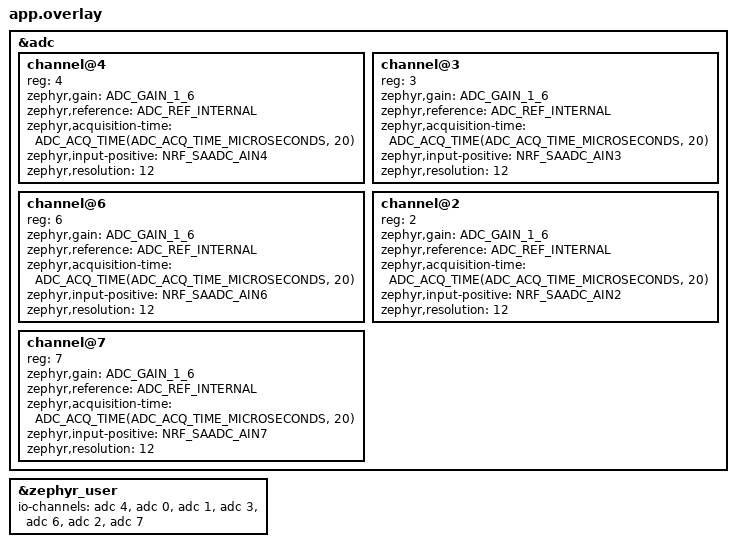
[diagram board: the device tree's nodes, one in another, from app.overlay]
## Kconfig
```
# lyra4-sp1 application Kconfig.

menu "LYRA-4"

# ---- the USB device's identity (M5a, src/sp1_usbd.c) ----
# Through M4e the console came up through Zephyr's sample helper, which hard-codes Zephyr's
# shared test vendor ID. These are ours. ⚠️ Change the PID whenever the set of USB functions
# changes (M5a added MIDI): hosts cache descriptors by VID/PID.
config SP1_USB_VID
	hex "USB vendor ID"
	default 0x2fe3
	help
	  0x2fe3 is Zephyr's test vendor ID, kept only until pid.codes (VID 0x1209,
	  free product IDs for open-source projects) grants LYRA-4 a PID of its own.

config SP1_USB_PID
	hex "USB product ID"
	default 0x5213
	help
	  0x5211 through M4e (console only); 0x5212 from M5a (console + MIDI);
	  0x5213 from M5c (console + MIDI + audio out). Interim: pid.codes
	  1209:4440 is requested (pidcodes/pidcodes.github.com#1301).

config SP1_USB_MANUFACTURER
	string "USB manufacturer string"
	default "Dreambored"

config SP1_USB_PRODUCT
	string "USB product string (the name hosts show for the device and its MIDI port)"
	default "LYRA-4"
	help
	  "lyra4-sp1" through v0.6.x; "LYRA-4" from M5c (Adara). DAWs remember MIDI routings by
	  port name, so a change means re-selecting the port once on each host.

config SP1_USB_MAX_POWER
	int "bMaxPower, in units of 2 mA"
	default 50
	range 0 250
	help
	  iOS rejects accessories claiming more than 100 mA over the camera adapter, and
	  the SP-1 runs from its own battery.

config SP1_AUDIO_BLOCK_FRAMES
	int "Audio block, in frames at 48 kHz"
	default 96
	range 48 240
	help
	  How much audio is rendered at a time: 96 = 2 ms (the default since #32; with 1 queued,
	  8 ms of latency), 240 = 5 ms (25 ms with 2 queued; v0.5.0). Must be a multiple of 48 (1 ms): whole
	  Plaits blocks, and whole 1 kHz groups for Marbles' X/Y. Latency is
	  (CONFIG_I2S_NRFX_TX_BLOCK_COUNT + 3) blocks -- see prj.conf.

config SP1_PLAITS_BLOCK
	int "Plaits block, in samples (12 or 24)"
	default 24
	range 12 24
	depends on SP1_PLAITS
	help
	  How many samples Plaits renders per call (upstream: 12). 24 (#32) halves Plaits'
	  per-call work and our per-Plaits-block glue; modulation, TRIG and MIDI placement move
	  to a 0.5 ms grid and Marbles runs at 2 kHz instead of 4. Every time constant of ours
	  that counted blocks (the TRIG pulse, Plaits' trigger delay, Additive's spectrum
	  update, Chords' crossfade, MIDI's clock and smoothing, Marbles' rate) is expressed in
	  time, so it is the same at either size. Only 12 and 24 are valid.

config SP1_TRIGGER_DELAY_SAMPLES
	int "Plaits' TRIG delay, in samples (whole Plaits blocks)"
	default 24
	range 0 96
	depends on SP1_PLAITS
	help
	  Upstream Plaits delays its TRIG input by 1 ms (48 samples) so a eurorack pitch CV
	  that lags its gate is still caught. In LYRA-4 every TRIG arrives with its pitch, but
	  Plaits averages its V/Oct input over two blocks, so with no delay a Marbles X -> V/Oct
	  strike catches the pitch half-way (host: Modal's attack -1 dB from the settled one,
	  against -18 dB at 0.5 ms; MIDI notes and the quantizer latch are unaffected even at 0).
	  24 = 0.5 ms keeps every attack as it was (#32). Must be whole Plaits blocks.

config SP1_PROFILE_ICACHE
	bool "Diagnostics: flash-cache misses per audio section"
	default n
	depends on SP1_PLAITS
	help
	  Adds a BLK log line with the flash cache's misses per millisecond of audio, by
	  section (#32): whether 2 ms blocks cost more because of per-call work or because the
	  instruction cache refills each time the code switches between Marbles, MIDI and the
	  engine. Reads the NVMC counter a few times per Plaits block (~0.05 % CPU). Off in
	  release builds.

config SP1_LOGBUF_KB
	int "Stored log, in KB of RAM"
	default 96
	range 4 160
	help
	  Everything printk writes is also kept in RAM, newest last, and played back when a
	  terminal next opens the console -- so a session with the USB port in another host's
	  hands (the OP-XY) is not lost (src/sp1_logbuf.h). 96 KB is ~14 minutes of a session.

config SP1_USB_THREADS_BELOW_AUDIO
	bool "Run Zephyr's USB threads below the audio thread (#32)"
	default y
	depends on UDC_NRF_OUT_FAST
	help
	  Moves the udc_nrfx and usbd threads from K_PRIO_COOP(8), above audio, to main's
	  priority, so enumeration, the console and control requests cannot push an audio
	  block over (src/sp1_usbd.c). Only with the MIDI fast path: MIDI must not wait on
	  these threads, or its timestamps would be up to a block late.

config SP1_MIDI
	bool "USB-MIDI in: notes into Plaits, CCs onto both modules (M5a)"
	default y
	depends on SP1_PLAITS
	help
	  A USB-MIDI 1.0 port (feldd's class, third_party/feldd) next to the console.
	  Notes play Plaits, CCs offset parameters on both modules, all configured by
	  config/midi.ini at build time. Costs nothing until a host sends something.
	  n: no MIDI function on the USB device at all.

config SP1_USB_AUDIO
	bool "USB audio out: the SP-1's output to the host, USB Audio Class 1.0 (M5c)"
	default y
	depends on SP1_PLAITS && UDC_NRF_ISO_IN_FAST
	help
	  The output the codecs get, after VOL, sent to the host as a 48 kHz 16-bit
	  stereo input (src/sp1_uac.c). Output only: nothing is received from the host.
	  Packets go out from the USB interrupt through the ISO IN fast path
	  (zephyr-patches/udc_nrf-fast-paths.patch), which is required. Costs nothing
	  until a host opens the stream.

config SP1_PLAITS
	bool "Plaits voice as the audio source (M3)"
	default y
	select CPP
	help
	  y: PLAY triggers the Plaits voice (2-op FM), faders are FREQUENCY /
	  TIMBRE / MORPH / HARMONICS, VOL+/- set the output level.
	  n: the M2 440 Hz test tone instead, with its PLAY / VOL controls, and
	  none of the Plaits code is compiled or linked.

	  This is the FALLBACK SWITCH. If the voice faults or overruns on hardware,
	  set CONFIG_SP1_PLAITS=n in prj.conf and rebuild: everything else in the
	  build (headphone mute, LEDs, power) stays exactly as it was.

config SP1_LYRA
	bool "LYRA-4 four-voice synth as the audio source (experimental)"
	default n
	depends on !SP1_PLAITS
	select CPP
	help
	  y: the LYRA-4 engine (third_party/lyra4) replaces the Plaits voice. Build with
	  lyra.conf (CONFIG_SP1_PLAITS=n, MIDI and USB audio off). Pages, arming and LEDs:
	  src/lyra_ctl.c. Power, charge LEDs, headphone and bootloader code is LYRA-4'.

config SP1_STRING_VOICES
	int "String engine: number of strings (Plaits kNumStrings)"
	range 1 3
	default 2
	depends on SP1_PLAITS
	help
	  How many strings Plaits' String engine rings at once. Upstream is 3.
	  Each TRIG plucks the next string round-robin, so this is how many
	  notes can overlap before the oldest one is re-plucked.

	  2 (default, M3e): every string costs the same, so 2 saves a third of
	  the engine -- 598.6 -> 427.3 instructions/sample in tools/plaits-bench,
	  about 90 % -> 65 % of the audio budget on the SP-1. At 3, String
	  measured 90 % average and 98.5 % peak: it played, with no headroom.

	  Applied at build time to a generated copy of string_engine.h; the
	  vendored file is not modified (see "Plaits overrides" in
	  firmware/CMakeLists.txt). Set it to 3 in prj.conf to A/B the original.

config SP1_PARTICLES
	int "Particle engine: number of particles (Plaits kNumParticles)"
	range 1 6
	default 2
	depends on SP1_PLAITS
	help
	  How many resonant "particles" Plaits' Particle engine runs. Upstream
	  is 6. Plaits divides the density by this count, so the rate of events
	  is the same; fewer means fewer pings ringing at different pitches at
	  once.

	  2 (default, M3h): at 3 (M3f) the SP-1 peaked at 83-100 %, all of it
	  below MORPH centre where the diffuser runs (Adara). Each particle is
	  ~43 instructions/sample. At 6 (upstream) it measured 86 % average /
	  97 % peak. The diffuser is skipped above MORPH centre in any case.

config SP1_MODAL_MODES
	int "Modal engine: number of resonator modes (Plaits kMaxNumModes)"
	range 4 24
	default 12
	depends on SP1_PLAITS
	help
	  Partials of Plaits' modal resonator. Upstream is 24. Must be a
	  multiple of 4 (the resonator renders modes in batches of 4; the build
	  checks). Fewer modes drop the highest partials: the body of a bell
	  stays, its shimmer goes.

	  12 (default, M3g): 8 measured 49 % average / 54 % peak on the SP-1
	  and sounded band-limited (Adara); each batch of 4 modes costs ~100
	  instructions/sample, ~16 %, so 12 is expected near 65 % / 70 %.
	  8 is the fallback. 16 would be ~80 % average -- over the target.

endmenu

source "Kconfig.zephyr"
```

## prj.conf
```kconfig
# lyra4-sp1 M0 — the safety floor.
#
# Deliberately minimal. No USB, no console, no audio, no ADC. Every option
# here either keeps the device recoverable or is required to boot at all.
# Things are ADDED in later milestones, never removed to fix a build.

# ---- Recoverability ----
# The watchdog is the final backstop for a hang on a device with no reset pin.
CONFIG_WATCHDOG=y
# k_sys_fatal_error_handler() in main.c turns any fault into a cold reboot.
CONFIG_REBOOT=y

# ---- Fault containment ----
# HW_STACK_PROTECTION reprograms the MPU stack guard on every context switch.
# sp1-tape-looper measured that at ~1 % at the corner and turned it off in
# favour of the cheaper STACK_SENTINEL canary (which Kconfig excludes while
# MPU_STACK_GUARD is on). M0 has CPU to spare and no audio deadline yet, so
# keep the stronger guard here and revisit at M2 when the deadline is real.
CONFIG_HW_STACK_PROTECTION=y

# ---- USB CDC ACM console (M1c) ----
# Exists to make two things possible that are miserable blind: calibrating the
# battery divider, and building the button-ladder threshold tables in M1d.
#
# device_next rather than the legacy CONFIG_USB_DEVICE_STACK: legacy is smaller but
# deprecated, mass storage later would need device_next anyway, and this is the path
# sp1-tape-looper proved on this board and this Zephyr version.
CONFIG_CONSOLE=y
CONFIG_PRINTK=y
CONFIG_SERIAL=y
CONFIG_UART_CONSOLE=y
CONFIG_UART_LINE_CTRL=y
CONFIG_UART_INTERRUPT_DRIVEN=y

CONFIG_USB_DEVICE_STACK_NEXT=y
CONFIG_USBD_CDC_ACM_CLASS=y
# The app owns the single USBD context; do not let the CDC SYS_INIT build a second
# private one that would fight for the controller.
CONFIG_CDC_ACM_SERIAL_INITIALIZE_AT_BOOT=n
CONFIG_HWINFO=y
# The device's identity (VID/PID, names, bMaxPower) is CONFIG_SP1_USB_* in firmware/Kconfig
# since M5a, set by src/sp1_usbd.c rather than Zephyr's sample helper.

# ---- USB-MIDI (M5a) ----
# feldd's MIDI 1.0 class (third_party/feldd) queues its transmit side in a ring buffer.
CONFIG_RING_BUFFER=y
# #32: MIDI is received in the USB interrupt (zephyr-patches/udc_nrf-fast-paths.patch):
# ~110 us of thread hand-offs per message down to a few us, and stamped in the interrupt.
# That frees Zephyr's USB threads to run below audio (CONFIG_SP1_USB_THREADS_BELOW_AUDIO,
# on by default with it).
CONFIG_UDC_NRF_OUT_FAST=y
# M5c: USB audio out sends every packet from the USB interrupt (Ryan Gilmore's ISO IN fast
# path, same patch). CONFIG_SP1_USB_AUDIO (default y) needs it.
CONFIG_UDC_NRF_ISO_IN_FAST=y

CONFIG_LOG=n
CONFIG_ASSERT=n

# The USB stack's init and printf need more main stack than the bare power build.
# 3 KB from M3 (was 2 KB): main now uses the FPU (fader smoothing), so every exception
# taken on its stack carries the extended FP frame, and it calls printk with more args.
CONFIG_MAIN_STACK_SIZE=3072

# ---- Clocking ----
# Matches what the bootloader leaves behind. Do not change without reading
# docs/SAFETY.md -- re-initialising bootloader-owned clocks is on the "do not"
# list for this board.
CONFIG_CLOCK_CONTROL=y
CONFIG_CLOCK_CONTROL_NRF_K32SRC_SYNTH=y


# ---- LED rows on hardware PWM (M1a) ----
# Hardware PWM costs no CPU (EasyDMA), unlike the software PWM sp1-tape-looper
# uses -- which needed a zero-latency IRQ to stop flicker and would compete with
# the audio deadline from M2 on. Do not replace this with a software PWM.
CONFIG_PWM=y
CONFIG_PWM_NRFX=y

# ---- Battery voltage (M1b) ----
# SAADC on AIN4. Only the battery channel for now; the faders join in M1c.
CONFIG_ADC=y

# ---- Output naming ----
# Renames build/zephyr/zephyr.{elf,bin,hex,map,...} to lyra4-sp1.{elf,bin,hex,map,...}.
# The build/zephyr/ subdirectory itself is unaffected -- that name comes from the
# Zephyr CMake target, not this option.
CONFIG_KERNEL_BIN_NAME="lyra4-sp1"

# ---- Audio output (M2) ----
# I2C to the two codecs (CS42L42 headphone at 0x48, TAS2505 speaker amp at 0x18),
# and the I2S stream as a CLOCK SLAVE on both clocks -- see sp1_audio.h for the
# topology. Same three options sp1-tape-looper proved on this board.
CONFIG_I2C=y
CONFIG_I2S=y
CONFIG_I2S_NRFX=y
# ---- latency (M5b, Adara: "over 30 ms is a no-go"; #32: 10 ms) ----
# Sound leaves LYRA-4 (queued blocks + 3) x the block length after what caused it: one block
# to place a MIDI message on time, the queued blocks, the DMA's next one and the one
# playing (sp1_audio.c). 5 ms x 4 queued was 35 ms, 5 ms x 2 was 25 ms (v0.5.0), 2 ms x 2 was
# 10 ms, and 2 ms x 1 is 8 ms (#32), affordable since Plaits renders 24-sample blocks. The block
# length is CONFIG_SP1_AUDIO_BLOCK_FRAMES (firmware/Kconfig). What it costs: a block that runs
# long has (queued + 1) x 2 = 4 ms -- 200 % of its budget -- before the output runs dry. The
# heaviest session measured (Chords, Marbles, OUTxAUX, drive, a CC stream; 2026-10-04) peaked at
# 96.8 %, and USB enumeration no longer runs above audio.
CONFIG_I2S_NRFX_TX_BLOCK_COUNT=1

# ---- CPU per thread, for the log (M5b diagnostics; src/sp1_threads.h) ----
# The audio sections cannot see what preempts them -- the USB stack runs above audio -- so
# every thread's share is counted at each context switch, on the DWT cycle counter (the
# kernel's own tick would be 30 us coarse). A few cycles per switch.
CONFIG_THREAD_RUNTIME_STATS=y
CONFIG_THREAD_RUNTIME_STATS_USE_TIMING_FUNCTIONS=y
CONFIG_TIMING_FUNCTIONS=y
CONFIG_THREAD_MONITOR=y
CONFIG_THREAD_NAME=y

# Floating-point unit. Nothing in M2 uses float -- the tone and the meter are
# integer-only on purpose -- but Plaits is float throughout from M3. Turning the FPU
# on HERE means M3 changes one thing (the synth), not two (the synth and the
# FP context-switch behaviour).
CONFIG_FPU=y
# Preserve FP registers across context switches. CONFIG_FPU alone is Zephyr's
# UNSHARED mode: FP state is not saved when threads switch. Plaits (float) will run in
# the audio thread, and any float in main, USB or an ISR would silently corrupt it --
# and with the hard-float ABI the compiler may use VFP registers for plain data moves
# too. Set now, with the FPU, so M3 does not inherit a latent corruption bug.
CONFIG_FPU_SHARING=y

# ---- M3: the Plaits voice ----
# The fallback switch: n = the M2 test tone, and no Plaits code is built at all.
CONFIG_SP1_PLAITS=y
# Plaits is C++ (no exceptions, no RTTI -- the Zephyr defaults) and needs <algorithm>
# and <cmath>, which the minimal C++ library does not provide.
CONFIG_CPP=y
CONFIG_STD_CPP14=y
CONFIG_GLIBCXX_LIBCPP=y
# ⚠️ The audio thread runs at K_PRIO_PREEMPT(0) and MUST outrank main, so main moves
# to 1. From M3 the audio work is ~half the CPU; at equal priority the ADC scan and
# every printk would compete with the audio deadline. See sp1_audio.h.
CONFIG_MAIN_THREAD_PRIORITY=1
```

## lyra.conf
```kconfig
# LYRA-4 build overlay:  west build ... -- -DOVERLAY... use: -DEXTRA_CONF_FILE=lyra.conf
CONFIG_SP1_PLAITS=n
CONFIG_SP1_LYRA=y
CONFIG_SP1_MIDI=n
CONFIG_SP1_USB_AUDIO=n
CONFIG_SP1_USB_PRODUCT="LYRA-4"
CONFIG_SP1_USB_MANUFACTURER="Dreambored"
```

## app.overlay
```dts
/*
 * lyra4-sp1 application overlay.
 *
 * M1d adds the four faders, APPENDED after the battery so it keeps io-channel
 * index 0 and sp1_batt.c never has to be renumbered.
 *
 * `reg` is chosen to equal the AIN number for the faders, which makes the mapping
 * readable against the schematic. The io-channel INDEX is what C uses, and the two
 * are deliberately different things -- see sp1_controls.c.
 *
 * Gain 1/6 + ADC_REF_INTERNAL matches the ladder channels in the board DTS, and
 * that pairing is load-bearing: published millivolt threshold tables are only
 * valid under the ADC configuration they were measured in. sp1-midi uses gain 1/4
 * with VDD/4 -- never mix the two.
 */

#include <zephyr/dt-bindings/adc/adc.h>
#include <zephyr/dt-bindings/adc/nrf-saadc.h>

&adc {
	/* Battery voltage, P0.28 / AIN4, via an on-board divider of UNKNOWN ratio.
	 * See sp1_batt.h for how to calibrate it without opening the device. */
	channel@4 {
		reg = <4>;
		zephyr,gain = "ADC_GAIN_1_6";
		zephyr,reference = "ADC_REF_INTERNAL";
		zephyr,acquisition-time = <ADC_ACQ_TIME(ADC_ACQ_TIME_MICROSECONDS, 20)>;
		zephyr,input-positive = <NRF_SAADC_AIN4>;
		zephyr,resolution = <12>;
	};
};

&adc {
	/* Fader 1, P0.05 / AIN3 */
	channel@3 {
		reg = <3>;
		zephyr,gain = "ADC_GAIN_1_6";
		zephyr,reference = "ADC_REF_INTERNAL";
		zephyr,acquisition-time = <ADC_ACQ_TIME(ADC_ACQ_TIME_MICROSECONDS, 20)>;
		zephyr,input-positive = <NRF_SAADC_AIN3>;
		zephyr,resolution = <12>;
	};
	/* Fader 2, P0.30 / AIN6 */
	channel@6 {
		reg = <6>;
		zephyr,gain = "ADC_GAIN_1_6";
		zephyr,reference = "ADC_REF_INTERNAL";
		zephyr,acquisition-time = <ADC_ACQ_TIME(ADC_ACQ_TIME_MICROSECONDS, 20)>;
		zephyr,input-positive = <NRF_SAADC_AIN6>;
		zephyr,resolution = <12>;
	};
	/* Fader 3, P0.04 / AIN2 */
	channel@2 {
		reg = <2>;
		zephyr,gain = "ADC_GAIN_1_6";
		zephyr,reference = "ADC_REF_INTERNAL";
		zephyr,acquisition-time = <ADC_ACQ_TIME(ADC_ACQ_TIME_MICROSECONDS, 20)>;
		zephyr,input-positive = <NRF_SAADC_AIN2>;
		zephyr,resolution = <12>;
	};
	/* Fader 4, P0.31 / AIN7 */
	channel@7 {
		reg = <7>;
		zephyr,gain = "ADC_GAIN_1_6";
		zephyr,reference = "ADC_REF_INTERNAL";
		zephyr,acquisition-time = <ADC_ACQ_TIME(ADC_ACQ_TIME_MICROSECONDS, 20)>;
		zephyr,input-positive = <NRF_SAADC_AIN7>;
		zephyr,resolution = <12>;
	};
};

&zephyr_user {
	/* ORDER IS THE C-VISIBLE INDEX. Battery must stay index 0.
	 *   0 battery   1 ladder-tracks   2 ladder-vol
	 *   3 fader1    4 fader2          5 fader3       6 fader4
	 * See the IO_* defines in sp1_controls.c -- they must match this order. */
	io-channels = <&adc 4>,
		      <&adc 0>, <&adc 1>,
		      <&adc 3>, <&adc 6>, <&adc 2>, <&adc 7>;
};
```

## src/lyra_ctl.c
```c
#include "lyra_ctl.h"
#include <string.h>

static float params[LYRA_P_COUNT];
static float pub_prev[LYRA_P_COUNT];
static bool  quantize, quantize_prev;
static uint32_t phase_ms;
/* Unarmed-fader touch detection, for the LEDs only: a T blinks only while its fader is being
 * moved without being armed. Reference position + a hold timer; never feeds the parameters. */
#define TOUCH_DELTA   0.010f    /* 1 % of travel from the reference counts as movement */
#define TOUCH_HOLD_MS 1200u     /* keep blinking this long after the last movement     */
static float    touch_ref[4];
static uint32_t touch_ms[4];
static int      touch_bank = -1;

/* Voice trigger mode. LATCH: T toggles. MOMENTARY: sounds while held ("••" + FFWD). */
static int      mode;
static uint8_t  mom[4];            /* bit0: T held, bit1: PLAY held */

/* Defaults: the LIRA-4 patch's, except the delay feedback (see LYRA4_CONTROL_MAP.md 3c). */
#define DEF_DFB 0.30f
static const float kDefaults[LYRA_UI_BANKS][LYRA_UI_FADERS] = {
	{ 0.4f, 0.6f, 0.5f, 0.5f },      /* page 0: tune 1-4                    */
	{ 0.0f, 0.0f, 0.5f, 0.5f },      /* page 1: mod12, mod34, sharp12, 34   */
	{ 0.5f, DEF_DFB, 0.5f, 0.1f },   /* page 2: time, feedback, mix, mod    */
	{ 0.6f, 0.7f, 0.5f, 0.5f },      /* page 3: lfo A, lfo B, drive, dmix   */
	{ 0.5f, 0.0f, 0.5f, 0.5f },      /* page 0 + "••": pitch, hold, -, -    */
};

static void set_defaults(void)
{
	memset(params, 0, sizeof(params));
	params[LYRA_P_SOURCE12] = 2.0f;        /* the other pair */
	params[LYRA_P_SOURCE34] = 2.0f;
	params[LYRA_P_VOLUME] = 1.0f;          /* output level is LYRA-4' VOL+/VOL- */
	params[LYRA_P_DSOURCE] = 2.0f;
}

void lyra_ctl_init(void)
{
	set_defaults();
	lyra_ui_init(kDefaults);
	quantize = quantize_prev = false;
	phase_ms = 0;
	touch_bank = -1;
	for (int i = 0; i < 4; i++) touch_ms[i] = 0u;
	mode = LYRA_MODE_LATCH;
	for (int i = 0; i < 4; i++) mom[i] = 0u;
	memcpy(pub_prev, params, sizeof(params));
}

void lyra_ctl_enter(const uint16_t raw[4])
{
	/* Voices are off on every entry to ON; toggles keep their state. */
	for (int i = 0; i < 4; i++) { params[LYRA_P_SENSOR1 + i] = 0.0f; mom[i] = 0u; }
	lyra_ui_enter(raw);
	touch_bank = -1;
}

int lyra_ctl_mode(void) { return mode; }

static void voice_on(int i) { params[LYRA_P_SENSOR1 + i] = 1.0f; }
static void voice_off(int i) { params[LYRA_P_SENSOR1 + i] = 0.0f; }

/* Changing mode silences everything so no voice is left latched or held by the old mode. */
static void set_mode(int m)
{
	mode = m;
	for (int i = 0; i < 4; i++) { voice_off(i); mom[i] = 0u; }
}

static float flip(float v) { return v > 0.5f ? 0.0f : 1.0f; }
static float cycle_src(float v) { int s = (int)(v + 0.5f); return (float)(s == 2 ? 0 : (s == 0 ? 1 : 2)); }

static void fill_from_banks(void)
{
	for (int i = 0; i < 4; i++) {
		params[LYRA_P_TUNE1 + i] = lyra_ui_value(0, i);
	}
	params[LYRA_P_MOD12]   = lyra_ui_value(1, 0);
	params[LYRA_P_MOD34]   = lyra_ui_value(1, 1);
	params[LYRA_P_SHARP12] = lyra_ui_value(1, 2);
	params[LYRA_P_SHARP34] = lyra_ui_value(1, 3);
	params[LYRA_P_DTIME]   = lyra_ui_value(2, 0);
	params[LYRA_P_DFB]     = lyra_ui_value(2, 1);
	params[LYRA_P_DMIXD]   = lyra_ui_value(2, 2);
	params[LYRA_P_DMOD]    = lyra_ui_value(2, 3);
	params[LYRA_P_LFOA]    = lyra_ui_value(3, 0);
	params[LYRA_P_LFOB]    = lyra_ui_value(3, 1);
	params[LYRA_P_DRIVE]   = lyra_ui_value(3, 2);
	params[LYRA_P_DMIX]    = lyra_ui_value(3, 3);
	params[LYRA_P_PITCH]   = lyra_ui_value(LYRA_UI_SHIFT, 0);
	params[LYRA_P_HOLD]    = lyra_ui_value(LYRA_UI_SHIFT, 1);
}

static void buttons(bool fn, uint32_t pressed, uint32_t released)
{
	const int pg = lyra_ui_page();
	const uint32_t tm[4] = { LYRA_B_T1, LYRA_B_T2, LYRA_B_T3, LYRA_B_T4 };

	/* Momentary releases count wherever you are: a held voice must always be able to close. */
	for (int i = 0; i < 4; i++) {
		if ((released & tm[i]) && (mom[i] & 1u)) mom[i] &= (uint8_t)~1u;
		if ((released & LYRA_B_PLAY) && (mom[i] & 2u)) mom[i] &= (uint8_t)~2u;
		if (mode == LYRA_MODE_MOMENTARY && mom[i] == 0u && params[LYRA_P_SENSOR1 + i] > 0.5f
		    && ((released & tm[i]) || (released & LYRA_B_PLAY))) voice_off(i);
	}

	if (fn && pg == 0 && (pressed & LYRA_B_FFWD)) {
		set_mode(mode == LYRA_MODE_MOMENTARY ? LYRA_MODE_LATCH : LYRA_MODE_MOMENTARY);
	}

	if (!fn) {
		if (pressed & LYRA_B_RWD)  lyra_ui_set_page((pg + LYRA_UI_PAGES - 1) % LYRA_UI_PAGES);
		if (pressed & LYRA_B_FFWD) lyra_ui_set_page((pg + 1) % LYRA_UI_PAGES);
	}
	if ((pressed & LYRA_B_PLAY) && !fn) {
		if (mode == LYRA_MODE_MOMENTARY) {
			for (int i = 0; i < 4; i++) { mom[i] |= 2u; voice_on(i); }
		} else {
			bool all_on = true;
			for (int i = 0; i < 4; i++) if (params[LYRA_P_SENSOR1 + i] < 0.5f) all_on = false;
			for (int i = 0; i < 4; i++) params[LYRA_P_SENSOR1 + i] = all_on ? 0.0f : 1.0f;
		}
	}
	const uint32_t t[4] = { LYRA_B_T1, LYRA_B_T2, LYRA_B_T3, LYRA_B_T4 };
	for (int i = 0; i < 4; i++) {
		if (!(pressed & t[i])) continue;
		if (fn) {
			if (pg != 0) continue;
			switch (i) {
			case 0: params[LYRA_P_FAST12] = flip(params[LYRA_P_FAST12]); break;
			case 1: params[LYRA_P_FAST34] = flip(params[LYRA_P_FAST34]); break;
			case 2: params[LYRA_P_VIBRATO] = flip(params[LYRA_P_VIBRATO]); break;
			default: quantize = !quantize; break;
			}
			continue;
		}
		switch (pg) {
		case 0:
				if (mode == LYRA_MODE_MOMENTARY) { mom[i] |= 1u; voice_on(i); }
				else { params[LYRA_P_SENSOR1 + i] = flip(params[LYRA_P_SENSOR1 + i]); }
				break;
		case 1:
			if (i == 0) params[LYRA_P_SOURCE12] = cycle_src(params[LYRA_P_SOURCE12]);
			if (i == 1) params[LYRA_P_SOURCE34] = cycle_src(params[LYRA_P_SOURCE34]);
			if (i == 2) params[LYRA_P_TOTALFB] = flip(params[LYRA_P_TOTALFB]);
			break;
		case 2:
			if (i == 0) params[LYRA_P_DWAVE] = flip(params[LYRA_P_DWAVE]);
			if (i == 1) params[LYRA_P_DSOURCE] = cycle_src(params[LYRA_P_DSOURCE]);
			break;
		default:
			if (i == 0) params[LYRA_P_LFOLINK] = flip(params[LYRA_P_LFOLINK]);
			if (i == 1) params[LYRA_P_LFOANDOR] = flip(params[LYRA_P_LFOANDOR]);
			break;
		}
	}
}

bool lyra_ctl_tick(uint32_t dt_ms, const uint16_t raw[4], bool scan_valid, bool ladder_active,
		   bool fn_held, uint32_t pressed, uint32_t released)
{
	phase_ms = (phase_ms + dt_ms) % 800u;
	(void)lyra_ui_tick(raw, scan_valid, ladder_active, fn_held);
	/* LED-only touch tracking. */
	if (lyra_ui_bank() != touch_bank) {
		touch_bank = lyra_ui_bank();
		for (int i = 0; i < 4; i++) { touch_ref[i] = lyra_ui_pos(i); touch_ms[i] = 0u; }
	}
	for (int i = 0; i < 4; i++) {
		const float d = lyra_ui_pos(i) - touch_ref[i];
		if (lyra_ui_armed(i)) {
			touch_ref[i] = lyra_ui_pos(i);
			touch_ms[i] = 0u;
		} else if (d > TOUCH_DELTA || d < -TOUCH_DELTA) {
			touch_ref[i] = lyra_ui_pos(i);
			touch_ms[i] = TOUCH_HOLD_MS;
		} else if (touch_ms[i] > 0u) {
			touch_ms[i] = touch_ms[i] > dt_ms ? touch_ms[i] - dt_ms : 0u;
		}
	}
	fill_from_banks();
	/* A ladder press is exactly when a button edge arrives; the edge itself is real. */
	buttons(fn_held, pressed, released);
	const bool changed = memcmp(pub_prev, params, sizeof(params)) != 0 || quantize != quantize_prev;
	memcpy(pub_prev, params, sizeof(params));
	quantize_prev = quantize;
	return changed;
}

const float *lyra_ctl_params(void) { return params; }
bool lyra_ctl_quantize(void) { return quantize; }

/* Three-way source selector (2 = default source, 0 = alternative source, 1 = off):
 * bright = default source, dim = alternative source, dark = off. */
static uint8_t tri_level(float v)
{
	const int s = (int)(v + 0.5f);
	return s == 2 ? LYRA_TRK_ON : (s == 0 ? LYRA_TRK_MID : 0u);
}

static uint8_t bin_level(float v) { return v > 0.5f ? LYRA_TRK_ON : 0u; }

/* Steady level shown by T1-T4 on the current page.
 *   page 1: voice on/off.
 *   page 2: T1, T2 source (other pair bright / LFO-or-feedback dim / off dark); T3 total feedback.
 *   page 3: T1 delay waveform; T2 delay source (LFO bright / own tap dim / off dark).
 *   page 4: T1 LFO link; T2 LFO and/or. */
static uint8_t track_level(int i)
{
	switch (lyra_ui_page()) {
	case 0: return bin_level(params[LYRA_P_SENSOR1 + i]);
	case 1: if (i == 0) return tri_level(params[LYRA_P_SOURCE12]);
		if (i == 1) return tri_level(params[LYRA_P_SOURCE34]);
		if (i == 2) return bin_level(params[LYRA_P_TOTALFB]);
		return 0u;
	case 2: if (i == 0) return bin_level(params[LYRA_P_DWAVE]);
		if (i == 1) return tri_level(params[LYRA_P_DSOURCE]);
		return 0u;
	default: if (i == 0) return bin_level(params[LYRA_P_LFOLINK]);
		if (i == 1) return bin_level(params[LYRA_P_LFOANDOR]);
		return 0u;
	}
}

void lyra_ctl_leds(uint8_t track[4], uint8_t play[4])
{
	const bool phase = phase_ms < 400u;
	if (lyra_ui_bank() == LYRA_UI_SHIFT) {
		/* "••" held on page 1: T1-T4 are the four switches, shown steady. Only the pitch and
		 * hold faders (0, 1) are live here; faders 2 and 3 are unused and never signal. */
		const bool sw[4] = { params[LYRA_P_FAST12] > 0.5f, params[LYRA_P_FAST34] > 0.5f,
				     params[LYRA_P_VIBRATO] > 0.5f, quantize };
		for (int i = 0; i < 4; i++) track[i] = sw[i] ? LYRA_TRK_ON : 0u;
		for (int i = 0; i < 4; i++) play[i] = 0u;
		/* Page LED (top) dims; it blinks only while an unarmed live fader (pitch, hold) is
		 * being moved. The second side LED shows momentary mode. */
		bool waiting = false;
		for (int i = 0; i <= 1; i++) if (!lyra_ui_armed(i) && touch_ms[i] > 0u) waiting = true;
		play[3] = waiting ? (phase ? LYRA_SIDE_DIM : LYRA_SIDE_LOW) : LYRA_SIDE_DIM;
		play[2] = (mode == LYRA_MODE_MOMENTARY) ? LYRA_SIDE_FULL : 0u;
		return;
	}
	for (int i = 0; i < 4; i++) {
		const uint8_t lvl = track_level(i);
		if (lyra_ui_armed(i) || touch_ms[i] == 0u) {
			track[i] = lvl;
		} else if (lvl >= LYRA_TRK_ON) {
			/* Unarmed fader being moved: slow blink. Bright states blink bright/low; dim and
			 * dark states blink their level (at least the dark-state glimmer) and dark. */
			track[i] = phase ? LYRA_TRK_ON : LYRA_TRK_ON_LO;
		} else {
			track[i] = phase ? (lvl > LYRA_TRK_OFF_HI ? lvl : LYRA_TRK_OFF_HI) : 0u;
		}
	}
	for (int i = 0; i < 4; i++) play[i] = 0u;
	/* Page 1 is the TOP side LED. LED index 0 is the "••" end and index 3 is next to PLAY, so
	 * the page order runs from index 3 down to index 0 (user: page 1 = top, page 4 = bottom). */
	play[3 - lyra_ui_page()] = (lyra_ui_bank() == LYRA_UI_SHIFT) ? LYRA_SIDE_DIM : LYRA_SIDE_FULL;
}
```

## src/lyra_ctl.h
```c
/*
 * LYRA-4 control layer: pages, latching voices, toggles, LEDs, parameter vector.
 * Plain C99, no OS. Sits on lyra_ui (fader arming). The LYRA-4 glue (main.c) feeds it
 * button edges and fader reads and publishes `params` to the audio thread.
 *
 * Parameter ids below MIRROR lyra4::Param (lyra4_engine.h); sp1_lyra.cc static_asserts that.
 * Control map: LYRA4_CONTROL_MAP.md. VOL+/VOL- (output level) and the "••" power gestures
 * stay in LYRA-4' main loop and are not handled here.
 */
#ifndef LYRA_CTL_H
#define LYRA_CTL_H

#include "lyra_ui.h"

enum {
	LYRA_P_TUNE1 = 0, LYRA_P_TUNE2, LYRA_P_TUNE3, LYRA_P_TUNE4, LYRA_P_PITCH,
	LYRA_P_MOD12, LYRA_P_MOD34, LYRA_P_SHARP12, LYRA_P_SHARP34,
	LYRA_P_SOURCE12, LYRA_P_SOURCE34, LYRA_P_TOTALFB,
	LYRA_P_HOLD, LYRA_P_VIBRATO, LYRA_P_FAST12, LYRA_P_FAST34,
	LYRA_P_SENSOR1, LYRA_P_SENSOR2, LYRA_P_SENSOR3, LYRA_P_SENSOR4,
	LYRA_P_VOLUME, LYRA_P_DRIVE, LYRA_P_DMIX,
	LYRA_P_DWAVE, LYRA_P_DSOURCE,
	LYRA_P_DMOD, LYRA_P_DFB, LYRA_P_DMIXD, LYRA_P_DTIME,
	LYRA_P_LFOA, LYRA_P_LFOB, LYRA_P_LFOLINK, LYRA_P_LFOANDOR,
	LYRA_P_COUNT
};

/* Button edges (pressed / released this tick; PLAY and T1-T4 matter for `released`). */
#define LYRA_B_PLAY 0x01u
#define LYRA_B_T1   0x02u
#define LYRA_B_T2   0x04u
#define LYRA_B_T3   0x08u
#define LYRA_B_T4   0x10u
#define LYRA_B_RWD  0x20u
#define LYRA_B_FFWD 0x40u

/* Voice trigger modes ("••" + FFWD = momentary; the same press again = latch). */
enum { LYRA_MODE_LATCH = 0, LYRA_MODE_MOMENTARY };
int   lyra_ctl_mode(void);

/* Quantized-tuning switch (page 0, "••" + T4). Not an engine Param: applied via Options. */
void  lyra_ctl_init(void);
void  lyra_ctl_enter(const uint16_t raw[4]);    /* entry to ON: voices off, faders disarmed */
/* One control tick. Returns true if `params` or `quantize` changed. */
bool  lyra_ctl_tick(uint32_t dt_ms, const uint16_t raw[4], bool scan_valid, bool ladder_active,
		    bool fn_held, uint32_t pressed, uint32_t released);
const float *lyra_ctl_params(void);
bool  lyra_ctl_quantize(void);
/* Side (play) row levels, 0..255. The page indicator and the mode LED are deliberately
 * dim: they are always on. The track row keeps full range. */
#define LYRA_SIDE_FULL 100u
#define LYRA_SIDE_DIM   45u     /* shift layer */
#define LYRA_SIDE_LOW   10u     /* low half of the "touching an unpicked fader" blink */
/* Track row (T1-T4) levels. Half the old full-brightness; the shutdown animation is untouched. */
#define LYRA_TRK_ON     130u
#define LYRA_TRK_MID     45u    /* three-way selectors: the alternative source */
#define LYRA_TRK_ON_LO   50u    /* low half of the blink on an "on" T */
#define LYRA_TRK_OFF_HI  40u    /* high half of the blink on an "off" T */
/* LED levels 0..255 for the track row (T1-T4) and the play row (page indicator). */
void  lyra_ctl_leds(uint8_t track[4], uint8_t play[4]);

#endif
```

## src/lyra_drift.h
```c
/* LYRA-4: "has a hand touched a fader since the mark?" that survives common-mode drift.
 *
 * The stock check (sp1_controls_activity) flags any fader that has moved SP1_TOUCH_COUNTS
 * (80) from the value it had when "••" went down, and that flag cancels the 3 s shutdown.
 * A loud, changing output loads the supply rail the faders are read from, so ALL four
 * faders read a little low (or high) together, in proportion to their value. LYRA holds
 * "••" for a long time while the sound is moving, so that drift can cross 80 counts with
 * no hand on anything.
 *
 * A hand moves one or two faders. Drift moves every fader by the same FACTOR. So: estimate
 * the common factor from the faders that are far enough off zero to measure it (median of
 * their now/mark ratios, needs at least 3), bound it, and judge each fader against
 * mark * factor. With fewer than 3 usable faders, or a factor outside the bound, the factor
 * is 1 and this is exactly the stock test.
 *
 * Pure function, no state, no Zephyr: host-tested in lyra_drifttest.c.
 */
#ifndef LYRA_DRIFT_H
#define LYRA_DRIFT_H

#include <stdint.h>

#define LYRA_DRIFT_TOUCH     80      /* same as SP1_TOUCH_COUNTS                          */
#define LYRA_DRIFT_MIN_MARK  1200    /* a fader below this says too little about gain     */
#define LYRA_DRIFT_G_MIN     0.93f   /* more drift than +-7 % is not drift we trust       */
#define LYRA_DRIFT_G_MAX     1.07f

/* Returns the index (0..3) of the first fader judged touched, or -1 if none.
 * `gain_out` (optional) receives the common factor that was used. */
static inline int lyra_fader_touched(const uint16_t now[4], const uint16_t mark[4], float *gain_out)
{
	float r[4];
	int n = 0;
	for (int i = 0; i < 4; i++) {
		if (mark[i] >= LYRA_DRIFT_MIN_MARK) {
			r[n++] = (float)now[i] / (float)mark[i];
		}
	}
	float g = 1.0f;
	if (n >= 3) {
		for (int a = 1; a < n; a++) {            /* insertion sort, n <= 4 */
			const float v = r[a];
			int b = a - 1;
			while (b >= 0 && r[b] > v) { r[b + 1] = r[b]; b--; }
			r[b + 1] = v;
		}
		g = (n == 3) ? r[1] : 0.5f * (r[1] + r[2]);
		if (g < LYRA_DRIFT_G_MIN || g > LYRA_DRIFT_G_MAX) {
			g = 1.0f;
		}
	}
	if (gain_out) {
		*gain_out = g;
	}
	for (int i = 0; i < 4; i++) {
		const float expect = (float)mark[i] * g;
		const float d = (float)now[i] - expect;
		if (d >= (float)LYRA_DRIFT_TOUCH || d <= -(float)LYRA_DRIFT_TOUCH) {
			return i;
		}
	}
	return -1;
}

#endif
```

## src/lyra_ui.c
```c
#include "lyra_ui.h"
#include <math.h>

static float stored[LYRA_UI_BANKS][LYRA_UI_FADERS];
static float pos[LYRA_UI_FADERS];
static float prev[LYRA_UI_FADERS];
static float lock_ref[LYRA_UI_FADERS];
static float lastraw[LYRA_UI_FADERS];
static bool  armed[LYRA_UI_FADERS];
static bool  locked[LYRA_UI_FADERS];
static int   page;
static int   bank;
static bool  seeded;

static float clamp01(float v) { return v < 0.0f ? 0.0f : (v > 1.0f ? 1.0f : v); }
static float to01(uint16_t r) { return clamp01((float)r / LYRA_UI_FULL); }

void lyra_ui_init(const float d[LYRA_UI_BANKS][LYRA_UI_FADERS])
{
	for (int b = 0; b < LYRA_UI_BANKS; b++)
		for (int i = 0; i < LYRA_UI_FADERS; i++)
			stored[b][i] = d ? clamp01(d[b][i]) : 0.5f;
	page = 0; bank = 0; seeded = false;
	for (int i = 0; i < LYRA_UI_FADERS; i++) { pos[i] = prev[i] = lock_ref[i] = 0.0f; armed[i] = false; locked[i] = false; }
}

/* Decide, for the bank now showing, which faders start armed or locked. */
static void disarm_all(void)
{
	for (int i = 0; i < LYRA_UI_FADERS; i++) {
		prev[i] = pos[i];
		lock_ref[i] = pos[i];
		if (fabsf(stored[bank][i] - pos[i]) <= LYRA_UI_WINDOW) {
			/* Already on the value: no jump possible beyond the window. */
			armed[i] = true;
			locked[i] = false;
		} else {
			armed[i] = false;
			locked[i] = true;
		}
	}
}

void lyra_ui_enter(const uint16_t raw[LYRA_UI_FADERS])
{
	for (int i = 0; i < LYRA_UI_FADERS; i++) { pos[i] = lastraw[i] = to01(raw[i]); }
	page = 0; bank = 0; seeded = true;
	disarm_all();
}

void lyra_ui_set_page(int p)
{
	if (p < 0 || p >= LYRA_UI_PAGES || p == page) return;
	page = p; bank = p;
	disarm_all();
}

uint32_t lyra_ui_tick(const uint16_t raw[LYRA_UI_FADERS], bool scan_valid,
		      bool ladder_active, bool shift_held)
{
	if (!seeded) return 0u;

	/* Shift layer exists on page 0 only. Entering or leaving it is a bank change. */
	const int want = (page == 0 && shift_held) ? LYRA_UI_SHIFT : page;
	if (want != bank) { bank = want; disarm_all(); }

	/* Discard: nothing from this tick is allowed to influence anything. */
	if (!scan_valid || ladder_active) return 0u;

	uint32_t ev = 0u;
	for (int i = 0; i < LYRA_UI_FADERS; i++) {
		const float now = to01(raw[i]);
		const float jump = fabsf(now - lastraw[i]);
		lastraw[i] = now;
		if (jump >= LYRA_UI_JUMP) {
			/* A quarter of travel in one tick is not a hand: re-seed, apply nothing. */
			pos[i] = prev[i] = lock_ref[i] = now;
			continue;
		}
		const float filt = pos[i] + LYRA_UI_LP * (now - pos[i]);
		pos[i] = filt;

		float *const s = &stored[bank][i];
		if (locked[i]) {
			if (fabsf(pos[i] - lock_ref[i]) > LYRA_UI_LOCK) locked[i] = false;
			prev[i] = pos[i];
			continue;
		}
		if (armed[i]) {
			if (pos[i] != *s) { *s = pos[i]; ev |= 1u << i; }
			prev[i] = pos[i];
			continue;
		}
		/* Disarmed and unlocked: arm on crossing or on reaching the window. */
		const bool crossed = ((prev[i] - *s) * (pos[i] - *s)) <= 0.0f;
		if (crossed || fabsf(pos[i] - *s) <= LYRA_UI_WINDOW) {
			armed[i] = true;
			*s = pos[i];
			ev |= 1u << i;
		}
		prev[i] = pos[i];
	}
	return ev;
}

int   lyra_ui_page(void)                 { return page; }
int   lyra_ui_bank(void)                 { return bank; }
float lyra_ui_value(int b, int i)        { return stored[b][i]; }
bool  lyra_ui_armed(int i)               { return armed[i]; }
float lyra_ui_pos(int i)                 { return pos[i]; }
```

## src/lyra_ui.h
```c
/*
 * LYRA-4 fader arming (control map section 3b). Plain C99, no OS, no heap, so the same
 * file builds on a desktop (lyra_uitest.c) and, later, inside the LYRA-4 tree.
 *
 * RULE: a fader never changes a parameter it was not holding.
 *  - Every fader is DISARMED on enter, on every page change and on the shift layer.
 *  - A disarmed fader writes nothing, however it is moved.
 *  - It arms when (a) it is within LYRA_UI_WINDOW of the stored value, or (b) its position
 *    CROSSES the stored value between two valid ticks. After arming it tracks 1:1.
 *  - After a bank change, a fader that is NOT already within the window is also locked
 *    until it has moved LYRA_UI_LOCK from where it was (a finger resting on it, or the
 *    low-pass tail of the last move, is not movement).
 *  - A tick with an invalid scan, or with a ladder button down (rail sag), is discarded:
 *    it does not feed the filter, arm, or write.
 *  - A single-tick jump over LYRA_UI_JUMP is a bad sample: re-seed, apply nothing.
 */
#ifndef LYRA_UI_H
#define LYRA_UI_H

#include <stdint.h>
#include <stdbool.h>

#define LYRA_UI_FADERS   4
#define LYRA_UI_PAGES    4
#define LYRA_UI_BANKS    5      /* 0..3 = pages, 4 = page 0 with the shift key held */
#define LYRA_UI_SHIFT    4

#define LYRA_UI_FULL     3701.0f   /* measured top of travel (LYRA-4 SP1_FADER_FULL)     */
#define LYRA_UI_LP       0.125f    /* one-pole per tick, as LYRA-4                       */
#define LYRA_UI_WINDOW   0.015f    /* arming window, fraction of travel (tunable)       */
#define LYRA_UI_LOCK     0.03f     /* movement that ends the post-change lock           */
#define LYRA_UI_JUMP     0.25f     /* one-tick move that is a bad sample                */

void  lyra_ui_init(const float defaults[LYRA_UI_BANKS][LYRA_UI_FADERS]); /* NULL = 0.5 */

/* Entry to ON. `raw` must come from a VALID scan (scan until valid first). Disarms all. */
void  lyra_ui_enter(const uint16_t raw[LYRA_UI_FADERS]);

/* Page 0..3. Disarms all faders. No-op if unchanged. */
void  lyra_ui_set_page(int page);

/* One control tick. Returns a bitmask of faders whose stored value changed this tick. */
uint32_t lyra_ui_tick(const uint16_t raw[LYRA_UI_FADERS], bool scan_valid,
		      bool ladder_active, bool shift_held);

int   lyra_ui_page(void);
int   lyra_ui_bank(void);                       /* page, or LYRA_UI_SHIFT              */
float lyra_ui_value(int bank, int fader);       /* stored value 0..1                    */
bool  lyra_ui_armed(int fader);                 /* LED: blink slowly when false         */
float lyra_ui_pos(int fader);                   /* filtered fader position 0..1         */

#endif
```

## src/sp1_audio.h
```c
/*
 * LYRA-4 — audio output: codecs, 48 kHz I2S, output level, headphone detect, and
 * the block loop that runs the synth voice (M3) or the fallback test tone.
 *
 * ---- clock topology (TE's own, and the only one proven on this board) ----
 * The 3.072 MHz oscillator (P0.13) drives the I2S bit clock. The CS42L42 headphone
 * codec is the FRAME master: it divides that clock by 64 to make a frame clock of
 * exactly 48 000 Hz. The nRF52840 I2S peripheral and the TAS2505 speaker amp are both
 * CLOCK SLAVES. sp1-tape-looper found the hard way that having the nRF master the
 * clocks instead (at ~47 619 Hz) crackled on the speaker and gave only noise on the
 * headphones.
 *
 * ---- bring-up order, copied exactly from the proven path. DO NOT "TIDY" IT ----
 *   1. release both codec resets, 20 ms
 *   2. oscillator ON, 5 ms          -> the bit clock now exists
 *   3. start the I2S stream         -> nRF waits as a slave; there is no frame yet
 *   4. configure the TAS2505        -> its PLL locks to the BIT clock, already live
 *   5. configure the CS42L42        -> it starts mastering the FRAME clock, and the
 *                                      stream the nRF queued in step 3 begins to flow
 * Step 3 before step 5 looks backwards and is not: the amp only needs the bit clock,
 * the nRF just waits for frames, and this is the order that works on hardware.
 *
 * ---- priority: audio OUTRANKS main (M3) ----
 * Audio runs at K_PRIO_PREEMPT(0); CONFIG_MAIN_THREAD_PRIORITY=1 in prj.conf puts the
 * main loop below it. In M2 both were 0 and time-sliced (TIMESLICE_PRIORITY=0, 20 ms
 * slices), which was fine for a sine at ~7 % of the CPU and not for Plaits at ~50 %:
 * a 430 us ADC scan or a printk stalled by the host could then sit in front of an
 * audio block. Now the audio thread takes the CPU whenever a block is due, and main
 * runs in the gaps.
 *
 * ---- and therefore the audio thread must NEVER spin ----
 * The main loop is what feeds the watchdog and runs power-off. A thread that spins
 * ABOVE it starves both.
 *
 * What an OVERRUN does (voice slower than real time) -- checked against the pinned
 * i2s_nrfx.c, and not what an earlier version of this comment claimed: the driver
 * misses a buffer ("next buffers not supplied"), the stream goes to I2S_STATE_ERROR,
 * i2s_write() then fails at once, and the write-failure path SLEEPS 2 ms per failure
 * and re-primes after 8. So main still gets time: the device stays up with broken,
 * stuttering audio and a slower control loop, and power-off keeps working. It does
 * NOT starve into a watchdog reset -- so when debugging an overrun in M4, look for
 * `fail`/`rst` climbing on the AUD line, not for a reboot. CONFIG_SP1_PLAITS=n builds
 * the known-good tone firmware.
 *
 * tape-looper's write-failure path does `free; continue` with no sleep, which spins if
 * writes fail instantly. Every path through this thread blocks or sleeps instead. See
 * sp1_audio.c.
 *
 * ---- start/stop are bounded, always ----
 * sp1_audio_stop() is on the POWER-OFF path (sp1_quiesce_peripherals calls it). It
 * never waits more than 50 ms for the thread, whatever state the thread is in, and
 * power-off proceeds regardless -- rule 5a: power-off does not depend on anything
 * else succeeding.
 */
#ifndef SP1_AUDIO_H
#define SP1_AUDIO_H

#include <stdint.h>
#include <stdbool.h>

/* Create the audio thread (it parks immediately) and enable the DWT cycle counter.
 * Once, at boot, after the power-on gate. Safe to call stop() before this. */
void sp1_audio_init(void);

/* Bring the audio path up: resets released, oscillator on, stream started, both
 * codecs configured. Call on every entry to ON -- the way into STANDBY powers all of
 * it down. Bounded: never blocks longer than ~1 s, feeds the watchdog while it waits.
 * Returns 0 on success, negative if the stream could not be started. */
int sp1_audio_start(void);

/* Stop the stream. On the power-off path: waits at most 50 ms for the thread, then
 * returns REGARDLESS. Safe to call when audio was never started. */
void sp1_audio_stop(void);

/* Halt the I2S peripheral at register level and disconnect its pins. ONLY on the way
 * to SYSTEM_OFF -- never STANDBY, because the driver applies its pinctrl once at boot
 * and would not restore the pins. See sp1_audio.c. */
void sp1_audio_halt_for_system_off(void);

/* Peak |sample| (0..32767) of everything produced since the last call, then reset.
 * For the meter. Lock-free: one atomic swap. */
uint32_t sp1_audio_take_peak(void);

/* ---- OUTPUT LEVEL (VOL+ / VOL-) ----
 * 3 dB steps, slewed in the audio path so a change never clicks. Step 0 = 0 dBFS; the
 * last step is mute. Every TWO steps is one meter band (6.02 dB). Applies to the synth
 * and to the fallback tone alike, and to speaker and headphones alike -- the speaker's
 * extra speaker trim is separate and fixed (SP1_SPK_ATTEN_HALF_DB in sp1_audio.c:
 * -9 dB in M3, -6 dB since M4a). */
/* The M2 440 Hz test tone exists only when neither voice is built. */
#if !defined(CONFIG_SP1_PLAITS) && !defined(CONFIG_SP1_LYRA)
#define SP1_TONE_FALLBACK 1
#endif
#define SP1_LEVEL_STEPS     12      /* 0 .. 10 = 0 .. -30 dB, 11 = mute */
#if defined(CONFIG_SP1_PLAITS)
#define SP1_LEVEL_DEFAULT    2      /* -6 dBFS                                */
#else
#define SP1_LEVEL_DEFAULT    4      /* -12 dBFS for the test tone, as in M2   */
#endif

void sp1_audio_level_step(int delta);  /* +1 = quieter by 3 dB, -1 = louder */
int  sp1_audio_level_get(void);
int  sp1_audio_level_db_x10(void);     /* tenths of dBFS, -9990 = mute      */

/* ---- the fallback test tone (CONFIG_SP1_PLAITS=n only): 440 Hz, off at start ---- */
void sp1_audio_tone_set(bool on);
bool sp1_audio_tone_on(void);

/* ---- headphone detect -> speaker mute (M3), and the USB audio mute (M5c) ----
 * Call from the main loop every tick while ON, after sp1_audio_start(). Polls the
 * CS42L42 jack sense every 40 ms, debounced, and powers the speaker down while a plug
 * is in -- or while a host is taking USB audio out (stream open AND packets flowing).
 * Headphones always play. Returns -1
 * (nothing new), 0 (unplugged), 1 (plugged), 2 (detect failed repeatedly: disabled for
 * this session, speaker ON -- the USB mute with it), 3 (a host started taking USB audio:
 * speaker off) or 4 (no host is taking it any more: speaker back on, unless headphones
 * are in). */
int sp1_audio_jack_poll(uint32_t elapsed_ms);
int sp1_audio_jack_state(void);        /* 1 in, 0 out, -1 unknown */
bool sp1_audio_speaker_on(void);       /* what the speaker amp is actually set to */

/* Block cost since the last call: worst and mean cycles per block. Read-and-clear. */
void sp1_audio_take_cycles(uint32_t *max, uint32_t *avg);

/* Where the blocks since the last call went (issue #22): mean and worst cycles per block
 * for each section, and how often the whole block ran over. Read-and-clear, like
 * sp1_audio_take_cycles(), and meant to be read in the same place.
 *
 *   ENG / MRB / POST   sp1_synth.h's sections
 *   RTE                the rest of sp1_synth_render(): Marbles -> Plaits routing, TRIG
 *   OUT                the rest of the block: gain ramp, stereo copy, meter peak
 *
 * `over` counts blocks that cost more than the budget; `over_run` is the longest run of
 * them in a row. A long run is what starves the main loop -- one late block is absorbed
 * by the I2S queue, a second of them is not. */
enum {
	SP1_SEC_ENG, SP1_SEC_MRB, SP1_SEC_RTE, SP1_SEC_POST, SP1_SEC_OUT, SP1_SEC_N
};
struct sp1_audio_sections {
	uint32_t avg[SP1_SEC_N];
	uint32_t max[SP1_SEC_N];
	uint32_t over;
	uint32_t over_run;
	/* #32: the once-per-audio-block part of rte (sp1_synth.h, `pre`), avg/max cycles. */
	uint32_t pre_avg, pre_max;
	uint32_t pre_midi_avg, pre_route_avg;   /* #32 B1: parts of pre, avg cycles */
	/* #32, CONFIG_SP1_PROFILE_ICACHE (zeros otherwise): flash-cache misses SUMMED over the
	 * window per section (index SP1_SEC_*; rte excludes pre, which is miss_pre), the blocks
	 * they came from, and the cache's own totals for every thread (NVMC IHIT / IMISS). */
	uint32_t miss[SP1_SEC_N];
	uint32_t miss_pre;
	uint32_t blocks;
	uint32_t icache_hit, icache_miss;
	/* #32: the slowest single engine call in the window (cycles), its Plaits engine, and
	 * whether it was the first call after an engine change. */
	uint32_t eng_worst;
	uint8_t eng_worst_engine;
	bool eng_worst_first;
};
void sp1_audio_take_sections(struct sp1_audio_sections *out);

/* ---- diagnostics ---- */
struct sp1_audio_stats {
	uint32_t blocks;         /* blocks handed to I2S                         */
	uint32_t write_fails;    /* i2s_write errors                             */
	uint32_t restarts;       /* stream drop + re-prime after repeated fails  */
	uint32_t cyc_max;        /* worst cycles spent generating one block      */
	uint32_t cyc_budget;     /* cycles available per block                   */
	int      cfg_rc;         /* last i2s_configure() result                  */
	bool     running;
	bool     tas_ok;         /* every TAS2505 write ACKed                    */
	bool     hp_ok;          /* CS42L42 identified and configured            */
};
void sp1_audio_stats(struct sp1_audio_stats *out);

#endif /* SP1_AUDIO_H */
```
